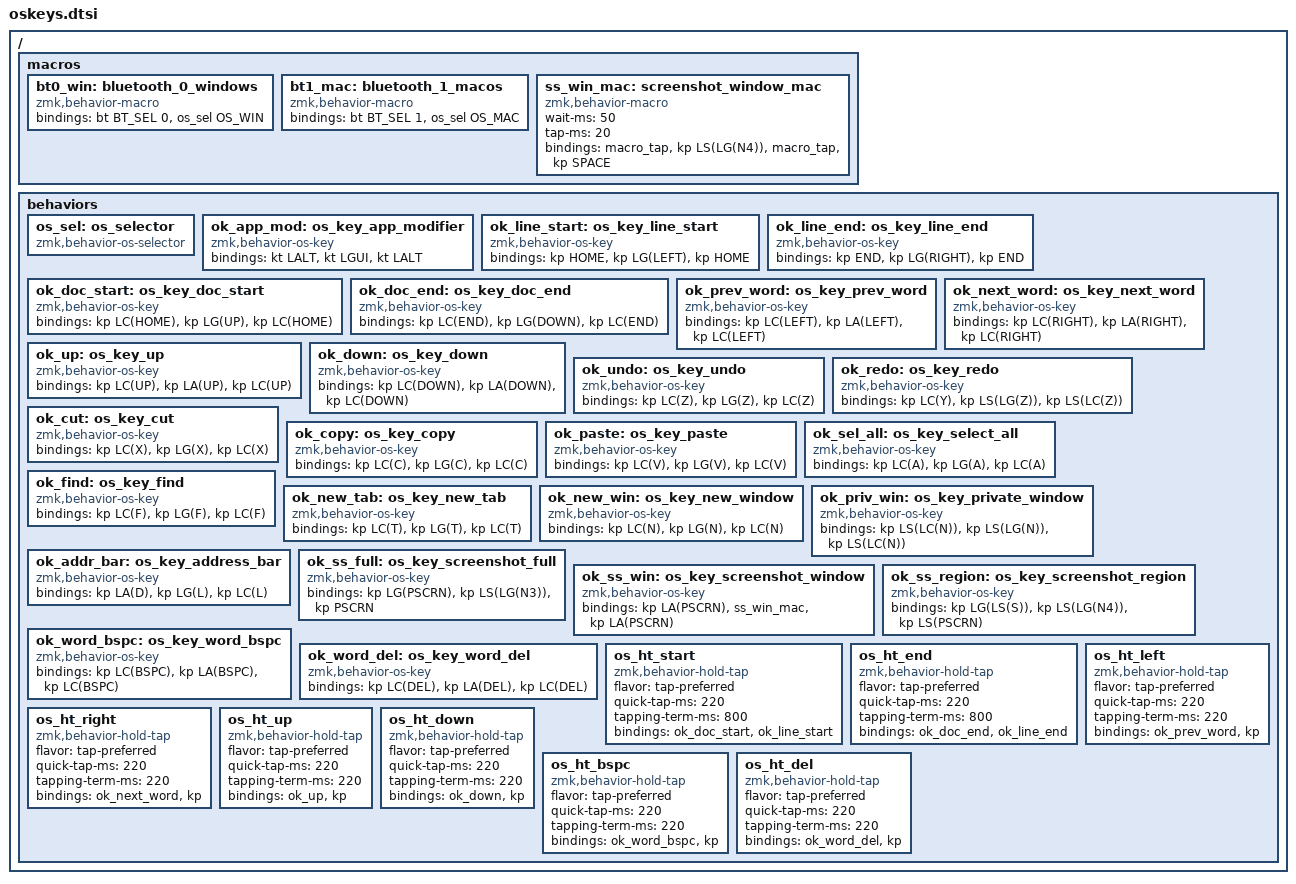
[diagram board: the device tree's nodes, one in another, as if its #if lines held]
#include <dt-bindings/zmk/oskey.h>

// Runtime OS selection for zmk-oskey.
#define OS_WIN_SEL &os_sel OS_WIN
#define OS_MAC_SEL &os_sel OS_MAC
#define OS_LIN_SEL &os_sel OS_LIN

// OS-aware navigation helpers.
#define OS_HT_START   &os_ht_start 0 0     // Tap: line start | Hold: document start.
#define OS_HT_END     &os_ht_end 0 0       // Tap: line end   | Hold: document end.
#define OS_HT_LEFT    &os_ht_left 0 LEFT   // Tap: left       | Hold: previous word.
#define OS_HT_RIGHT   &os_ht_right 0 RIGHT // Tap: right      | Hold: next word.
#define OS_HT_UP      &os_ht_up 0 UP       // Tap: up         | Hold: Ctrl/Option+Up.
#define OS_HT_DOWN    &os_ht_down 0 DOWN   // Tap: down       | Hold: Ctrl/Option+Down.
#define OS_HT_BSPC    &os_ht_bspc 0 BSPC   // Tap: backspace  | Hold: delete previous word.
#define OS_HT_DEL     &os_ht_del 0 DEL     // Tap: delete     | Hold: delete next word.

/ {
  macros {
#ifdef CONFIG_WIRELESS
    bt0_win: bluetooth_0_windows {
      compatible = "zmk,behavior-macro";
      #binding-cells = <0>;
      bindings = <&bt BT_SEL 0>, <&os_sel OS_WIN>;
    };

    bt1_mac: bluetooth_1_macos {
      compatible = "zmk,behavior-macro";
      #binding-cells = <0>;
      bindings = <&bt BT_SEL 1>, <&os_sel OS_MAC>;
    };
#endif

    ss_win_mac: screenshot_window_mac {
      compatible = "zmk,behavior-macro";
      #binding-cells = <0>;
      wait-ms = <50>;
      tap-ms = <20>;
      bindings = <&macro_tap &kp LS(LG(N4))>,
                 <&macro_tap &kp SPACE>;
    };
  };

  behaviors {
    os_sel: os_selector {
      compatible = "zmk,behavior-os-selector";
      #binding-cells = <1>;
    };

    ok_app_mod: os_key_app_modifier {
      compatible = "zmk,behavior-os-key";
      #binding-cells = <0>;
      bindings = <&kt LALT>, <&kt LGUI>, <&kt LALT>;
    };

    ok_line_start: os_key_line_start {
      compatible = "zmk,behavior-os-key";
      #binding-cells = <0>;
      bindings = <&kp HOME>, <&kp LG(LEFT)>, <&kp HOME>;
    };

    ok_line_end: os_key_line_end {
      compatible = "zmk,behavior-os-key";
      #binding-cells = <0>;
      bindings = <&kp END>, <&kp LG(RIGHT)>, <&kp END>;
    };

    ok_doc_start: os_key_doc_start {
      compatible = "zmk,behavior-os-key";
      #binding-cells = <0>;
      bindings = <&kp LC(HOME)>, <&kp LG(UP)>, <&kp LC(HOME)>;
    };

    ok_doc_end: os_key_doc_end {
      compatible = "zmk,behavior-os-key";
      #binding-cells = <0>;
      bindings = <&kp LC(END)>, <&kp LG(DOWN)>, <&kp LC(END)>;
    };

    ok_prev_word: os_key_prev_word {
      compatible = "zmk,behavior-os-key";
      #binding-cells = <0>;
      bindings = <&kp LC(LEFT)>, <&kp LA(LEFT)>, <&kp LC(LEFT)>;
    };

    ok_next_word: os_key_next_word {
      compatible = "zmk,behavior-os-key";
      #binding-cells = <0>;
      bindings = <&kp LC(RIGHT)>, <&kp LA(RIGHT)>, <&kp LC(RIGHT)>;
    };

    ok_up: os_key_up {
      compatible = "zmk,behavior-os-key";
      #binding-cells = <0>;
      bindings = <&kp LC(UP)>, <&kp LA(UP)>, <&kp LC(UP)>;
    };

    ok_down: os_key_down {
      compatible = "zmk,behavior-os-key";
      #binding-cells = <0>;
      bindings = <&kp LC(DOWN)>, <&kp LA(DOWN)>, <&kp LC(DOWN)>;
    };

    ok_undo: os_key_undo {
      compatible = "zmk,behavior-os-key";
      #binding-cells = <0>;
      bindings = <&kp LC(Z)>, <&kp LG(Z)>, <&kp LC(Z)>;
    };

    ok_redo: os_key_redo {
      compatible = "zmk,behavior-os-key";
      #binding-cells = <0>;
      bindings = <&kp LC(Y)>, <&kp LS(LG(Z))>, <&kp LS(LC(Z))>;
    };

    ok_cut: os_key_cut {
      compatible = "zmk,behavior-os-key";
      #binding-cells = <0>;
      bindings = <&kp LC(X)>, <&kp LG(X)>, <&kp LC(X)>;
    };

    ok_copy: os_key_copy {
      compatible = "zmk,behavior-os-key";
      #binding-cells = <0>;
      bindings = <&kp LC(C)>, <&kp LG(C)>, <&kp LC(C)>;
    };

    ok_paste: os_key_paste {
      compatible = "zmk,behavior-os-key";
      #binding-cells = <0>;
      bindings = <&kp LC(V)>, <&kp LG(V)>, <&kp LC(V)>;
    };

    ok_sel_all: os_key_select_all {
      compatible = "zmk,behavior-os-key";
      #binding-cells = <0>;
      bindings = <&kp LC(A)>, <&kp LG(A)>, <&kp LC(A)>;
    };

    ok_find: os_key_find {
      compatible = "zmk,behavior-os-key";
      #binding-cells = <0>;
      bindings = <&kp LC(F)>, <&kp LG(F)>, <&kp LC(F)>;
    };

    ok_new_tab: os_key_new_tab {
      compatible = "zmk,behavior-os-key";
      #binding-cells = <0>;
      bindings = <&kp LC(T)>, <&kp LG(T)>, <&kp LC(T)>;
    };

    ok_new_win: os_key_new_window {
      compatible = "zmk,behavior-os-key";
      #binding-cells = <0>;
      bindings = <&kp LC(N)>, <&kp LG(N)>, <&kp LC(N)>;
    };

    ok_priv_win: os_key_private_window {
      compatible = "zmk,behavior-os-key";
      #binding-cells = <0>;
      bindings = <&kp LS(LC(N))>, <&kp LS(LG(N))>, <&kp LS(LC(N))>;
    };

    ok_addr_bar: os_key_address_bar {
      compatible = "zmk,behavior-os-key";
      #binding-cells = <0>;
      bindings = <&kp LA(D)>, <&kp LG(L)>, <&kp LC(L)>;
    };

    ok_ss_full: os_key_screenshot_full {
      compatible = "zmk,behavior-os-key";
      #binding-cells = <0>;
      bindings = <&kp LG(PSCRN)>, <&kp LS(LG(N3))>, <&kp PSCRN>;
    };

    ok_ss_win: os_key_screenshot_window {
      compatible = "zmk,behavior-os-key";
      #binding-cells = <0>;
      bindings = <&kp LA(PSCRN)>, <&ss_win_mac>, <&kp LA(PSCRN)>;
    };

    ok_ss_region: os_key_screenshot_region {
      compatible = "zmk,behavior-os-key";
      #binding-cells = <0>;
      bindings = <&kp LG(LS(S))>, <&kp LS(LG(N4))>, <&kp LS(PSCRN)>;
    };

    ok_word_bspc: os_key_word_bspc {
      compatible = "zmk,behavior-os-key";
      #binding-cells = <0>;
      bindings = <&kp LC(BSPC)>, <&kp LA(BSPC)>, <&kp LC(BSPC)>;
    };

    ok_word_del: os_key_word_del {
      compatible = "zmk,behavior-os-key";
      #binding-cells = <0>;
      bindings = <&kp LC(DEL)>, <&kp LA(DEL)>, <&kp LC(DEL)>;
    };

    os_ht_start: os_ht_start {
      compatible = "zmk,behavior-hold-tap";
      #binding-cells = <2>;
      flavor = "tap-preferred";
      quick-tap-ms = <220>;
      tapping-term-ms = <800>;
      bindings = <&ok_doc_start>, <&ok_line_start>;
    };

    os_ht_end: os_ht_end {
      compatible = "zmk,behavior-hold-tap";
      #binding-cells = <2>;
      flavor = "tap-preferred";
      quick-tap-ms = <220>;
      tapping-term-ms = <800>;
      bindings = <&ok_doc_end>, <&ok_line_end>;
    };

    os_ht_left: os_ht_left {
      compatible = "zmk,behavior-hold-tap";
      #binding-cells = <2>;
      flavor = "tap-preferred";
      quick-tap-ms = <220>;
      tapping-term-ms = <220>;
      bindings = <&ok_prev_word>, <&kp>;
    };

    os_ht_right: os_ht_right {
      compatible = "zmk,behavior-hold-tap";
      #binding-cells = <2>;
      flavor = "tap-preferred";
      quick-tap-ms = <220>;
      tapping-term-ms = <220>;
      bindings = <&ok_next_word>, <&kp>;
    };

    os_ht_up: os_ht_up {
      compatible = "zmk,behavior-hold-tap";
      #binding-cells = <2>;
      flavor = "tap-preferred";
      quick-tap-ms = <220>;
      tapping-term-ms = <220>;
      bindings = <&ok_up>, <&kp>;
    };

    os_ht_down: os_ht_down {
      compatible = "zmk,behavior-hold-tap";
      #binding-cells = <2>;
      flavor = "tap-preferred";
      quick-tap-ms = <220>;
      tapping-term-ms = <220>;
      bindings = <&ok_down>, <&kp>;
    };

    os_ht_bspc: os_ht_bspc {
      compatible = "zmk,behavior-hold-tap";
      #binding-cells = <2>;
      flavor = "tap-preferred";
      quick-tap-ms = <220>;
      tapping-term-ms = <220>;
      bindings = <&ok_word_bspc>, <&kp>;
    };

    os_ht_del: os_ht_del {
      compatible = "zmk,behavior-hold-tap";
      #binding-cells = <2>;
      flavor = "tap-preferred";
      quick-tap-ms = <220>;
      tapping-term-ms = <220>;
      bindings = <&ok_word_del>, <&kp>;
    };
  };
};
